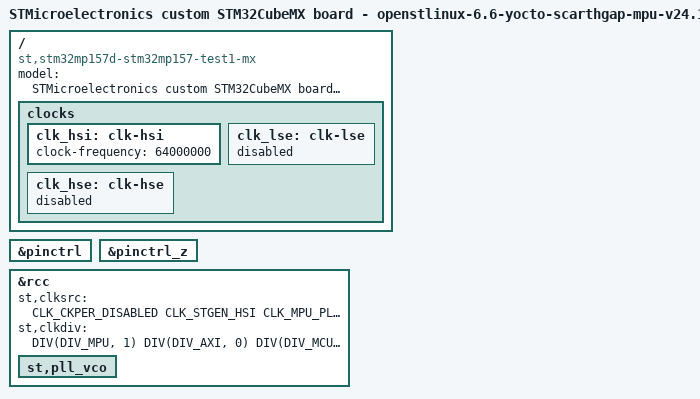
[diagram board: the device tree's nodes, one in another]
// SPDX-License-Identifier: (GPL-2.0-or-later OR BSD-3-Clause)
/*
 * Copyright (C) 2025, STMicroelectronics - All Rights Reserved
 * Author: STM32CubeMX code generation for STMicroelectronics.
 */

/* For more information on Device Tree configuration, please refer to
 * https://wiki.st.com/stm32mpu/wiki/Category:Device_tree_configuration
 */

/dts-v1/;

#include <dt-bindings/pinctrl/stm32-pinfunc.h>
#include <dt-bindings/clock/stm32mp1-clksrc.h>

#include "stm32mp157.dtsi"
#include "stm32mp15xd.dtsi"
#include "stm32mp15xxac-pinctrl.dtsi"
/* !!! log : Warning - DDR not configured: unknown DDR dtsi  !!! */
/*#include "???-ddr.dtsi"*/

/* USER CODE BEGIN includes */
/* USER CODE END includes */

/ {
	model = "STMicroelectronics custom STM32CubeMX board - openstlinux-6.6-yocto-scarthgap-mpu-v24.11.06";
	compatible = "st,stm32mp157d-stm32mp157-test1-mx", "st,stm32mp157";

	/* !!! log : Warning - no DDR config found: 'memory' node not generated  !!! */

	/*
	memory@??? {
		reg = < ??? >;
	};
	*/

	/* USER CODE BEGIN root */
	/* USER CODE END root */

	clocks {
		/* USER CODE BEGIN clocks */
		/* USER CODE END clocks */

		clk_hsi: clk-hsi {
			clock-frequency = <64000000>;

			/* USER CODE BEGIN clk_hsi */
			/* USER CODE END clk_hsi */
		};
		clk_lse: clk-lse {
			status = "disabled";

			/* USER CODE BEGIN clk_lse */
			/* USER CODE END clk_lse */
		};
		clk_hse: clk-hse {
			status = "disabled";

			/* USER CODE BEGIN clk_hse */
			/* USER CODE END clk_hse */
		};
	};

}; /*root*/

&pinctrl {
	/* USER CODE BEGIN pinctrl */
	/* USER CODE END pinctrl */
};

&pinctrl_z {
	/* USER CODE BEGIN pinctrl_z */
	/* USER CODE END pinctrl_z */
};

&rcc {
	status = "okay";

	/* USER CODE BEGIN rcc */
	/* USER CODE END rcc */

	st,clksrc = <
		CLK_CKPER_DISABLED
		CLK_STGEN_HSI
		CLK_MPU_PLL1P
		CLK_AXI_HSI
		CLK_MCU_HSI
	>;
	st,clkdiv = <
		DIV(DIV_MPU, 1)
		DIV(DIV_AXI, 0)
		DIV(DIV_MCU, 0)
		DIV(DIV_APB1, 0)
		DIV(DIV_APB2, 0)
		DIV(DIV_APB3, 0)
		DIV(DIV_APB4, 0)
		DIV(DIV_APB5, 0)
		DIV(DIV_RTC, 0)
		DIV(DIV_MCO1, 0)
		DIV(DIV_MCO2, 0)
	>;
	st,pll_vco {
		/* USER CODE BEGIN rcc_st-pll_vco */
		/* USER CODE END rcc_st-pll_vco */
	};

};

/* USER CODE BEGIN addons */
/* USER CODE END addons */

